AUTOSAR XML (schema 00049)
standard types defined: uint8
package /Observation1SWC_Config/Types/ImplementationDataTypes
  impl type TYP_ExchangedData: category=VALUE, base-type=uint8
package /Observation1SWC_Config/Types/SwAddrMethods
  sw addr method CODE: section-type=CODE
  sw addr method CONST: section-type=CONST
  sw addr method VAR: section-type=VAR
package /Observation1SWC_Config/Types/Units
  unit NoUnit: factor-si-to-unit=1, offset-si-to-unit=0
package /Observation1SWC_Config/Interfaces
  sender receiver interface IF_ExchangedData
    data DE_ExchangedData: category=VALUE, sw-calibration-access=READ-ONLY, type=TYP_ExchangedData
    data DE_ExchangedEvent: category=VALUE, sw-calibration-access=READ-ONLY, sw-impl-policy=QUEUED, type=TYP_ExchangedData
package /Observation1SWC_Config/SWCs
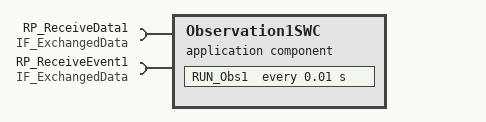
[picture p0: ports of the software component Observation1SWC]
  application sw component type Observation1SWC
    require port RP_ReceiveData1: nonqueued-receiver-com-spec{data-element=DE_ExchangedData, init-value=0}, required-interface=IF_ExchangedData
    require port RP_ReceiveEvent1: queued-receiver-com-spec{data-element=DE_ExchangedEvent, queue-length=2}, required-interface=IF_ExchangedData
    behavior Observation1SWC_IB: handle-termination-and-restart=NO-SUPPORT
      timing event Ev_Ti_RUN_Obs1: start-on-event=RUN_Obs1, period=0.01
      runnable RUN_Obs1
        data-receive-point-by-arguments:
          access VDP_Receive1: accessed-variable=RP_ReceiveEvent1.DE_ExchangedEvent
        data-receive-point-by-values:
          access VDP_ExplRead1: accessed-variable=RP_ReceiveData1.DE_ExchangedData
